# STM32U3C5xx register map
File version: 1.0
Registers are 32-bit, read-write, reset 0x0 unless marked. A register's access mark holds for its fields unless they carry their own. Offsets are from the block's base; [hi:lo] are bit positions; {n}, {i} and the like mark numbered series; 'fields as' and 'values as' point back to an identical list.

## SAI1 — Serial Audio Interface
Base 0x40015400
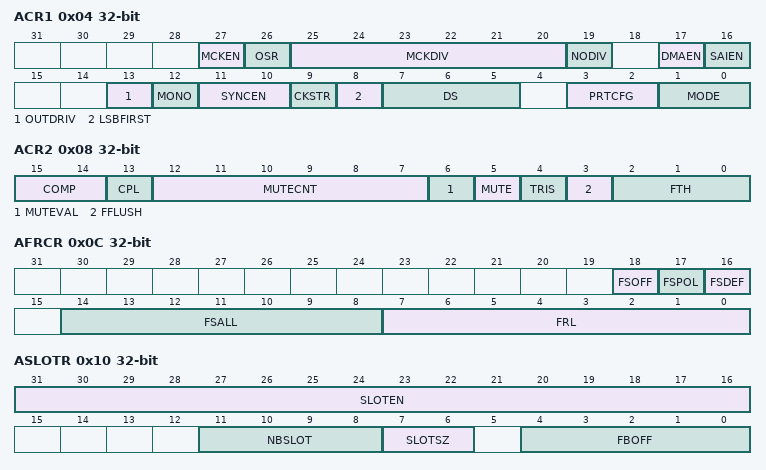
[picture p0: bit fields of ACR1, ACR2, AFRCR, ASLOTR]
0x04 ACR1 — SAI block x configuration register 1
  [27] MCKEN — Master clock generation enable
  [26] OSR — Oversampling ratio for master clock
  [25:20] MCKDIV — MCKDIV[5:0] (Master ClocK Divider)
  [19] NODIV — No Divider Configuration
  [17] DMAEN — DMA enable
  [16] SAIEN — Audio Block enable
  [13] OUTDRIV — Output Drive
  [12] MONO — Mono mode
  [11:10] SYNCEN — SYNCEN[1:0](SYNChronization ENable)
  [9] CKSTR — ClocK STRobing edge
  [8] LSBFIRST — LSB First Configuration
  [7:5] DS — DS[1:0] bits (Data Size)
  [3:2] PRTCFG — PRTCFG[1:0] bits (Protocol Configuration)
  [1:0] MODE — MODE[1:0] bits (Audio Block Mode)
0x08 ACR2 — SAI block x configuration register 2
  [15:14] COMP — COMP[1:0] (Companding mode)
  [13] CPL — CPL mode
  [12:7] MUTECNT — MUTECNT[5:0] (MUTE counter)
  [6] MUTEVAL — Muate value
  [5] MUTE — Mute mode
  [4] TRIS — TRIState Management on data line
  [3] FFLUSH — Fifo FLUSH
  [2:0] FTH — FTH[2:0](Fifo THreshold)
0x0C AFRCR — SAI block x frame configuration register
  [18] FSOFF — Frame Synchronization OFFset
  [17] FSPOL — Frame Synchronization POLarity
  [16] FSDEF — Frame Synchronization Definition
  [14:8] FSALL — FRL[6:0] (Frame synchronization active level length)
  [7:0] FRL — FRL[7:0](Frame length)
0x10 ASLOTR — SAI block x slot register
  [31:16] SLOTEN — SLOTEN[15:0] (Slot Enable)
  [11:8] NBSLOT — NBSLOT[3:0] (Number of Slot in audio Frame)
  [7:6] SLOTSZ — SLOTSZ[1:0] (Slot size)
  [4:0] FBOFF — FRL[4:0](First Bit Offset)
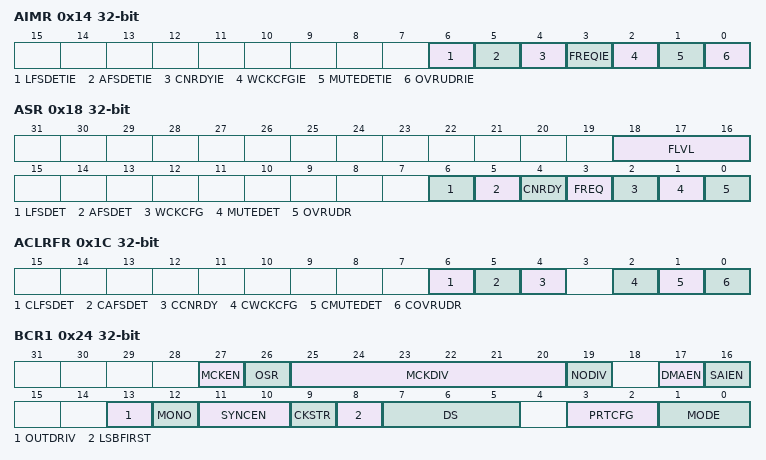
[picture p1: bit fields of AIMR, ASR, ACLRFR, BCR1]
0x14 AIMR — SAI block x interrupt mask register
  [6] LFSDETIE — Late frame synchronization detection interrupt enable
  [5] AFSDETIE — Anticipated frame synchronization detection interrupt enable
  [4] CNRDYIE — Codec not ready interrupt enable
  [3] FREQIE — FIFO request interrupt enable
  [2] WCKCFGIE — Wrong Clock Configuration interrupt enable
  [1] MUTEDETIE — Mute detection interrupt enable
  [0] OVRUDRIE — Overrun underrun interrupt enable
0x18 ASR — SAI block x status register
  [18:16] FLVL — FLVL[2:0] (FIFO Level Threshold)
  [6] LFSDET — Late frame synchronization detection
  [5] AFSDET — Anticipated frame synchronization detection
  [4] CNRDY — Codec not ready
  [3] FREQ — FIFO request
  [2] WCKCFG — Wrong Clock Configuration
  [1] MUTEDET — Mute detection
  [0] OVRUDR — Overrun underrun
0x1C ACLRFR — SAI block x clear flag register
  [6] CLFSDET — Clear Late frame synchronization detection
  [5] CAFSDET — Clear Anticipated frame synchronization detection
  [4] CCNRDY — Clear Codec not ready
  [2] CWCKCFG — Clear Wrong Clock Configuration
  [1] CMUTEDET — Clear Mute detection
  [0] COVRUDR — Clear Overrun underrun
0x20 ADR — SAI block x data register
  [31:0] DATA
0x24 BCR1 — SAI block x configuration register 1
  fields as ACR1
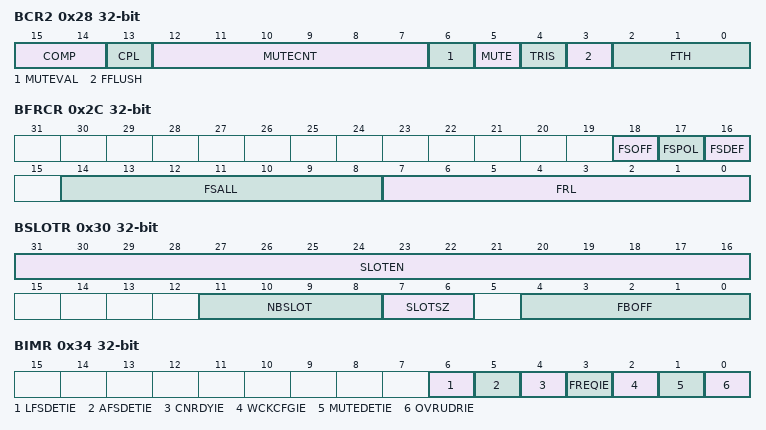
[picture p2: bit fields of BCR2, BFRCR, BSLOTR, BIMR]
0x28 BCR2 — SAI block x configuration register 2
  fields as ACR2
0x2C BFRCR — SAI block x frame configuration register
  fields as AFRCR
0x30 BSLOTR — SAI block x slot register
  fields as ASLOTR
0x34 BIMR — SAI block x interrupt mask register
  fields as AIMR
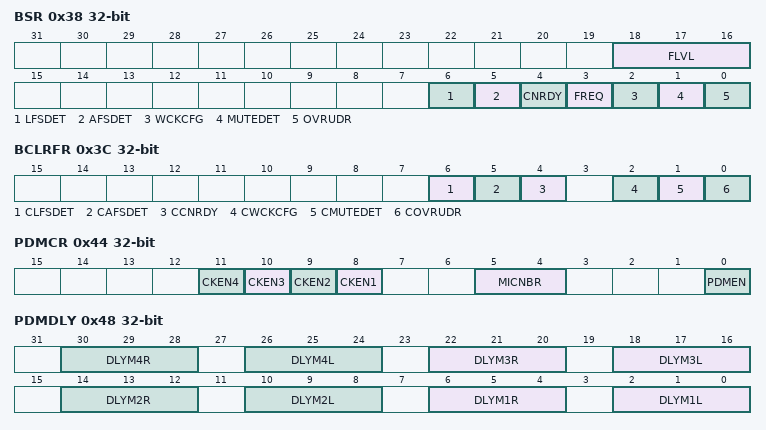
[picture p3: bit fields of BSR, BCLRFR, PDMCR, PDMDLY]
0x38 BSR — SAI block x status register
  fields as ASR
0x3C BCLRFR — SAI block x clear flag register
  fields as ACLRFR
0x40 BDR — SAI block x data register
  [31:0] DATA
0x44 PDMCR — SAI PDM control register
  [n+7] CKEN{n} (n=1..4) — Clock {n} enable
  [5:4] MICNBR — MICNBR[1:0] (Number of microphones)
  [0] PDMEN — PDM enable
0x48 PDMDLY — SAI PDM delay register
  [8n-2:8n-4] DLYM{n}R (n=1..4) — DLYM{n}R[2:0] (Delay line adjust for right microphone of pair {n})
  [8n-6:8n-8] DLYM{n}L (n=1..4) — DLYM{n}L[2:0] (Delay line adjust for left microphone of pair {n})

## USB_DRD_FS — Universal Serial Bus Full Speed Dual Role Device
Base 0x40016000
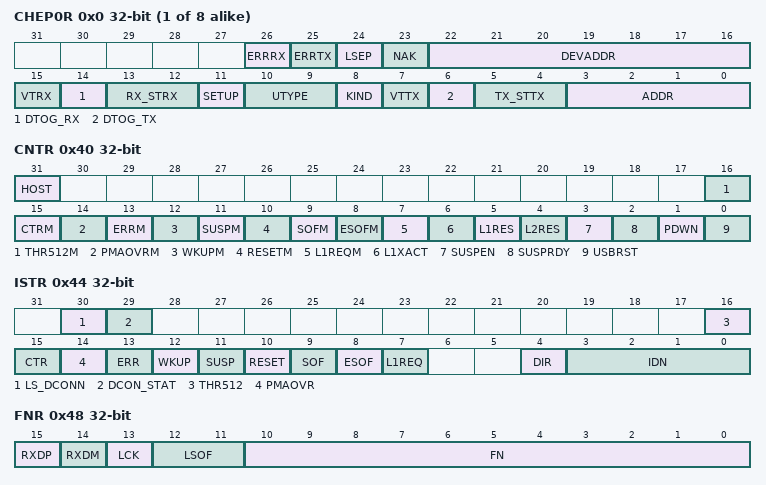
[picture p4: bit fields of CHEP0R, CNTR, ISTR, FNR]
{0x0+4i} CHEP{i}R (i=0..7) — USB Channel/Endpoint {i} register
  [26] ERRRX — Receive error
  [25] ERRTX — Transmit error
  [24] LSEP — Low Speed Endpoint (host with Hub Only)
  [23] NAK — Previous NAK detected
  [22:16] DEVADDR
  [15] VTRX — USB valid transaction received Mask
  [14] DTOG_RX — Data Toggle, for reception transfers Mask
  [13:12] RX_STRX — Status bits, for reception transfers Mask
  [11] SETUP — Setup transaction completed Mask
  [10:9] UTYPE — USB type of transaction Mask
  [8] KIND — EndPoint KIND Mask
  [7] VTTX — Valid USB transaction transmitted Mask
  [6] DTOG_TX — Data Toggle, for transmission transfers Mask
  [5:4] TX_STTX — Status bits, for transmission transfers Mask
  [3:0] ADDR — Endpoint address Mask
0x40 CNTR — Control register
  [31] HOST — Host Mode
  [16] THR512M — 512byte Threshold interrupt mask
  [15] CTRM — Correct Transfer Mask
  [14] PMAOVRM — DMA OVeR/underrun Mask
  [13] ERRM — ERRor Mask
  [12] WKUPM — WaKe UP Mask
  [11] SUSPM — SUSPend Mask
  [10] RESETM — RESET Mask
  [9] SOFM — Start Of Frame Mask
  [8] ESOFM — Expected Start Of Frame Mask
  [7] L1REQM — LPM L1 state request interrupt Mask
  [6] L1XACT — Host LPM L1 transaction request Mask
  [5] L1RES — LPM L1 Resume request/ Remote Wakeup Mask
  [4] L2RES — L2 Remote Wakeup / Resume driver Mask
  [3] SUSPEN — Suspend state enable Mask
  [2] SUSPRDY — Suspend state effective Mask
  [1] PDWN — Power DoWN Mask
  [0] USBRST — USB Reset Mask
0x44 ISTR — Interrupt status register
  [30] LS_DCONN — LS_DCONN Mask
  [29] DCON_STAT — Device Connection status (connected/Disconnected) don't cause an interrupt
  [16] THR512 — 512byte threshold interrupt (used with isochrnous single buffer )
  [15] CTR — Correct TRansfer (clear-only bit) Mask
  [14] PMAOVR — PMA OVeR/underrun (clear-only bit) Mask
  [13] ERR — ERRor (clear-only bit) Mask
  [12] WKUP — WaKe UP (clear-only bit) Mask
  [11] SUSP — SUSPend (clear-only bit) Mask
  [10] RESET — RESET Mask
  [9] SOF — Start Of Frame (clear-only bit) Mask
  [8] ESOF — Expected Start Of Frame (clear-only bit) Mask
  [7] L1REQ — LPM L1 state request Mask
  [4] DIR — DIRection of transaction (read-only bit) Mask
  [3:0] IDN — EndPoint IDentifier (read-only bit) Mask
0x48 FNR — Frame number register
  [15] RXDP — status of D+ data line Mask
  [14] RXDM — status of D- data line Mask
  [13] LCK — LoCKed Mask
  [12:11] LSOF — Lost SOF Mask
  [10:0] FN — Frame Number Mask
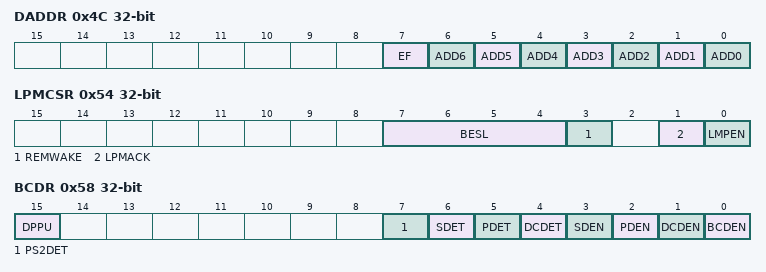
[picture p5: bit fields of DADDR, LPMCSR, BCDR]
0x4C DADDR — Device address register
  [7] EF — Enable Function Mask
  [n] ADD{n} (n=0..6) — Bit {n} Mask
0x54 LPMCSR — LPM Control and Status register
  [7:4] BESL — BESL value received with last ACKed LPM Token Mask
  [3] REMWAKE — bRemoteWake value received with last ACKed LPM Token Mask
  [1] LPMACK — LPM Token acknowledge enable Mask
  [0] LMPEN — LPM support enable Mask
0x58 BCDR — Battery Charging detector register
  [15] DPPU — DP Pull-up Enable Mask
  [7] PS2DET — PS2 port or proprietary charger detected Mask
  [6] SDET — Secondary detection (SD) status Mask
  [5] PDET — Primary detection (PD) status Mask
  [4] DCDET — Data contact detection (DCD) status Mask
  [3] SDEN — Secondary detection (SD) mode enable Mask
  [2] PDEN — Primary detection (PD) mode enable Mask
  [1] DCDEN — Data contact detection (DCD) mode enable Mask
  [0] BCDEN — Battery charging detector (BCD) enable Mask
